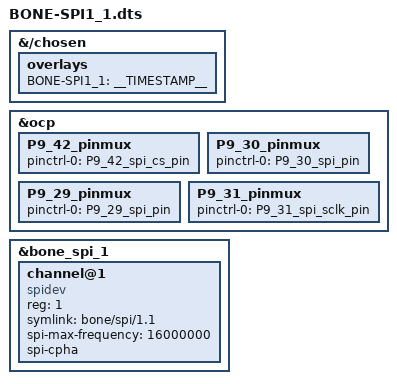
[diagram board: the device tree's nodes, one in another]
/*
 * Copyright (C) 2020 Deepak Khatri <deepaklorkhatri7@gmail.com>
 * See Cape Interface Spec page for more info on Bone Buses
 * https://elinux.org/Beagleboard:BeagleBone_cape_interface_spec
 *
 * Virtual cape for /dev/bone/spi/1.1
 *
 * This program is free software; you can redistribute it and/or modify
 * it under the terms of the GNU General Public License version 2 as
 * published by the Free Software Foundation.
 */

/dts-v1/;
/plugin/;

/*
* Helper to show loaded overlays under: /proc/device-tree/chosen/overlays/
*/
&{/chosen} {
    overlays {
        BONE-SPI1_1 = __TIMESTAMP__;
    };
};

/*
 * Update the default pinmux of the pins.
 * See these files for the phandles (&P9_* & &P8_*)
 * BeagleBoard-DeviceTrees/v4.19.x-ti-overlays/src/arm/am335x-bone-common-univ.dtsi
 * BeagleBoard-DeviceTrees/v4.19.x-ti-overlays/src/arm/am572x-bone-common-univ.dtsi
 */
&ocp {
	P9_42_pinmux { pinctrl-0 = <&P9_42_spi_cs_pin>; }; /* CS */
    P9_30_pinmux { pinctrl-0 = <&P9_30_spi_pin>; }; /* MOSI */
    P9_29_pinmux { pinctrl-0 = <&P9_29_spi_pin>; };	/* MISO */
    P9_31_pinmux { pinctrl-0 = <&P9_31_spi_sclk_pin>; }; /* CLK */
};

/*
 * See these files for the phandles (&bone_*) and other bone bus nodes
 * BeagleBoard-DeviceTrees/v4.19.x-ti-overlays/src/arm/bbai-bone-buses.dtsi
 * BeagleBoard-DeviceTrees/v4.19.x-ti-overlays/src/arm/bbb-bone-buses.dtsi
 */
&bone_spi_1 {
	status = "okay";
    #address-cells = <1>;
    #size-cells = <0>;

	channel@1 {
		reg = <1>;
		compatible = "spidev";
		symlink = "bone/spi/1.1";
		spi-max-frequency = <16000000>;
        spi-cpha;
	};
};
